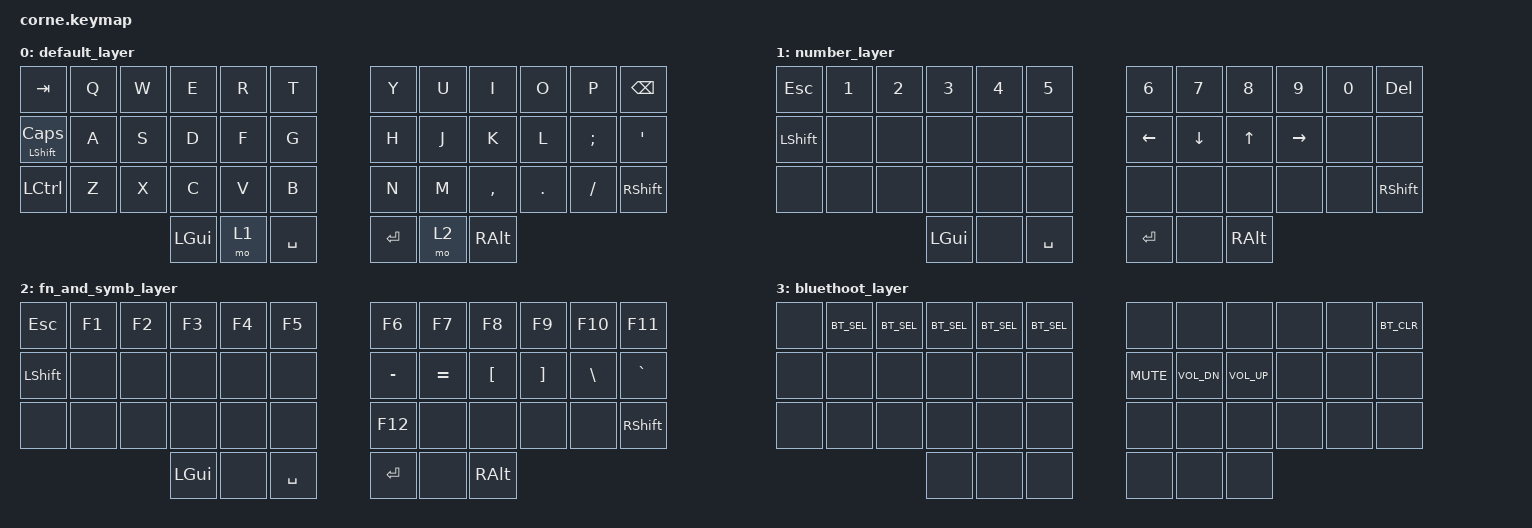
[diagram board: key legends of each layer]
/*
 * Copyright (c) 2020 The ZMK Contributors
 *
 * SPDX-License-Identifier: MIT
 */

#include <behaviors.dtsi>
#include <dt-bindings/zmk/keys.h>
#include <dt-bindings/zmk/bt.h>

/ {
        keymap {
                compatible = "zmk,keymap";

                default_layer {
// -----------------------------------------------------------------------------------------
// |  TAB |  Q  |  W  |  E  |  R  |  T  |   |  Y  |  U   |  I  |  O  |  P  | BSPC |
// | SHFT |  A  |  S  |  D  |  F  |  G  |   |  H  |  J   |  K  |  L  |  ;  |  '   |
// | CTRL |  Z  |  X  |  C  |  V  |  B  |   |  N  |  M   |  ,  |  .  |  /  | SHFT |
//                    | GUI | LWR | SPC |   | ENT | RSE  | ALT |
                        bindings = <
   &kp TAB   &kp Q &kp W &kp E &kp R &kp T   &kp Y &kp U  &kp I     &kp O   &kp P    &kp BSPC
   &mt LSHFT CAPS &kp A &kp S &kp D &kp F &kp G   &kp H &kp J  &kp K     &kp L   &kp SEMI &kp SQT
   &kp LCTRL &kp Z &kp X &kp C &kp V &kp B   &kp N &kp M  &kp COMMA &kp DOT &kp FSLH &kp RSHFT
                  &kp LGUI &mo 1 &kp SPACE   &kp RET &mo 2 &kp RALT
                        >;
                };

                number_layer {
// -----------------------------------------------------------------------------------------
// |  ESC |  1  |  2  |  3  |  4  |  5  |   |  6  |  7  |  8  |  9  |  0  | DEL  |
// | SHFT |     |     |     |     |     |   | LFT | DWN |  UP | RGT |     |      |
// |      |     |     |     |     |     |   |     |     |     |     |     | SHFT |
//                    | GUI |     | SPC |   | ENT |     | ALT |
                        bindings = <
   &kp ESC    &kp N1      &kp N2       &kp N3       &kp N4       &kp N5      &kp N6   &kp N7   &kp N8 &kp N9    &kp N0 &kp DEL
   &kp LSHFT  &none      &none       &none       &none       &none      &kp LEFT &kp DOWN &kp UP &kp RIGHT &none &none
   &none  &none      &none       &none       &none       &none      &none   &none   &none &none    &none &kp RSHFT
                                    &kp LGUI     &none       &kp SPACE      &kp RET  &none   &kp RALT
                        >;
                };

                fn_and_symb_layer {
// -----------------------------------------------------------------------------------------
// |  ESC |  F1 |  F2 |  F3 |  F4 |  F5 |   |  F6 |  F7 |  F8 |  F9 | F10 | F11  |
// | SHFT |     |     |     |     |     |   |  -  |  =  |  [  |  ]  |  \  |  `   |
// |      |     |     |     |     |     |   | F12 |     |     |     |     | SHFT |
//                    | GUI |     | SPC |   | ENT |     | ALT |


                        bindings = <
   &kp  ESC  &kp F1   &kp F2 &kp F3   &kp F4   &kp F5      &kp F6    &kp F7    &kp F8    &kp F9   &kp F10  &kp F11
   &kp LSHFT &none   &none &none   &none   &none      &kp MINUS &kp EQUAL &kp LBKT  &kp RBKT &kp BSLH &kp GRAVE
   &none    &none   &none &none   &none   &none      &kp F12   &none    &none    &none   &none   &kp RSHFT
                             &kp LGUI &none   &kp SPACE   &kp RET   &none    &kp RALT
                        >;
                };

                bluethoot_layer {
// -----------------------------------------------------------------------------------------
// |      | BT1 | BT2 | BT3 | BT4 | BT5 |   |     |     |     |     |     | BTCLR|
// |      |     |     |     |     |     |   |CMUTE|VOLDW|VOLUP|     |     |  `   |
// |      |     |     |     |     |     |   |     |     |     |     |     |      |
//                    |     |     |     |   |     |     |     |
                        bindings = <
   &none  &kp BT_SEL 0 &kp BT_SEL 1 &kp BT_SEL 2 &kp BT_SEL 3 &kp BT_SEL 4     &none      &none        &none          &none   &none   &kp BT_CLR
   &none  &none       &none       &none       &none       &none           &kp C_MUTE  &kp C_VOL_DN  &kp C_VOL_UP    &none   &none   &none
   &none  &none       &none       &none       &none       &none           &none      &none        &none          &none   &none   &none
                                     &none       &none       &none           &none      &none        &none
                        >;
                };
        
                extra2 {
                    status = "reserved";
                };
        };
};
